AUTOSAR XML (schema 4-3-0)
package /Comp_FDC_ARPkg
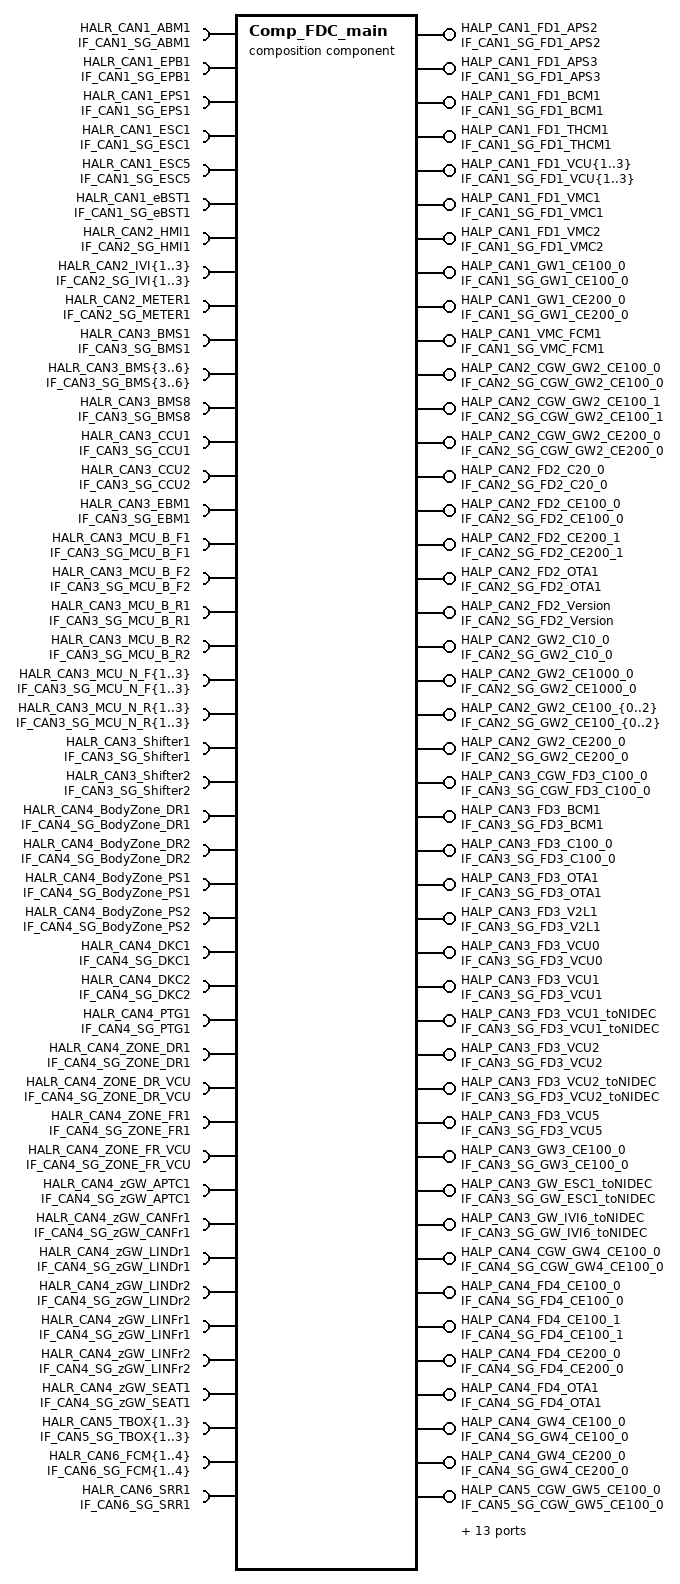
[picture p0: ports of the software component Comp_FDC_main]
  composition sw component type Comp_FDC_main
    63 x provide port:
      HALP_CAN1_FD1_APS2: nonqueued-sender-com-spec{data-element=CAN1_SG_FD1_APS2, handle-out-of-range=DEFAULT, init-value=constant-reference=Init_CAN1_SG_FD1_APS2}, provided-interface=IF_CAN1_SG_FD1_APS2
      HALP_CAN1_FD1_APS3: nonqueued-sender-com-spec{data-element=CAN1_SG_FD1_APS3, handle-out-of-range=DEFAULT, init-value=constant-reference=Init_CAN1_SG_FD1_APS3}, provided-interface=IF_CAN1_SG_FD1_APS3
      HALP_CAN1_FD1_BCM1: nonqueued-sender-com-spec{data-element=CAN1_SG_FD1_BCM1, handle-out-of-range=DEFAULT, init-value=constant-reference=Init_CAN1_SG_FD1_BCM1}, provided-interface=IF_CAN1_SG_FD1_BCM1
      HALP_CAN1_FD1_THCM1: nonqueued-sender-com-spec{data-element=CAN1_SG_FD1_THCM1, handle-out-of-range=DEFAULT, init-value=constant-reference=Init_CAN1_SG_FD1_THCM1}, provided-interface=IF_CAN1_SG_FD1_THCM1
      HALP_CAN1_FD1_VCU{1..3}: nonqueued-sender-com-spec{data-element=CAN1_SG_FD1_VCU{1..3}, handle-out-of-range=DEFAULT, init-value=constant-reference=Init_CAN1_SG_FD1_VCU{1..3}}, provided-interface=IF_CAN1_SG_FD1_VCU{1..3}
      HALP_CAN1_FD1_VMC1: nonqueued-sender-com-spec{data-element=CAN1_SG_FD1_VMC1, handle-out-of-range=DEFAULT, init-value=constant-reference=Init_CAN1_SG_FD1_VMC1}, provided-interface=IF_CAN1_SG_FD1_VMC1
      HALP_CAN1_FD1_VMC2: nonqueued-sender-com-spec{data-element=CAN1_SG_FD1_VMC2, handle-out-of-range=DEFAULT, init-value=constant-reference=Init_CAN1_SG_FD1_VMC2}, provided-interface=IF_CAN1_SG_FD1_VMC2
      HALP_CAN1_GW1_CE100_0: nonqueued-sender-com-spec{data-element=CAN1_SG_GW1_CE100_0, handle-out-of-range=DEFAULT, init-value=constant-reference=Init_CAN1_SG_GW1_CE100_0}, provided-interface=IF_CAN1_SG_GW1_CE100_0
      HALP_CAN1_GW1_CE200_0: nonqueued-sender-com-spec{data-element=CAN1_SG_GW1_CE200_0, handle-out-of-range=DEFAULT, init-value=constant-reference=Init_CAN1_SG_GW1_CE200_0}, provided-interface=IF_CAN1_SG_GW1_CE200_0
      HALP_CAN1_VMC_FCM1: nonqueued-sender-com-spec{data-element=CAN1_SG_VMC_FCM1, handle-out-of-range=DEFAULT, init-value=constant-reference=Init_CAN1_SG_VMC_FCM1}, provided-interface=IF_CAN1_SG_VMC_FCM1
      HALP_CAN2_CGW_GW2_CE100_0: nonqueued-sender-com-spec{data-element=CAN2_SG_CGW_GW2_CE100_0, handle-out-of-range=DEFAULT, init-value=constant-reference=Init_CAN2_SG_CGW_GW2_CE100_0}, provided-interface=IF_CAN2_SG_CGW_GW2_CE100_0
      HALP_CAN2_CGW_GW2_CE100_1: nonqueued-sender-com-spec{data-element=CAN2_SG_CGW_GW2_CE100_1, handle-out-of-range=DEFAULT, init-value=constant-reference=Init_CAN2_SG_CGW_GW2_CE100_1}, provided-interface=IF_CAN2_SG_CGW_GW2_CE100_1
      HALP_CAN2_CGW_GW2_CE200_0: nonqueued-sender-com-spec{data-element=CAN2_SG_CGW_GW2_CE200_0, handle-out-of-range=DEFAULT, init-value=constant-reference=Init_CAN2_SG_CGW_GW2_CE200_0}, provided-interface=IF_CAN2_SG_CGW_GW2_CE200_0
      HALP_CAN2_FD2_C20_0: nonqueued-sender-com-spec{data-element=CAN2_SG_FD2_C20_0, handle-out-of-range=DEFAULT, init-value=constant-reference=Init_CAN2_SG_FD2_C20_0}, provided-interface=IF_CAN2_SG_FD2_C20_0
      HALP_CAN2_FD2_CE100_0: nonqueued-sender-com-spec{data-element=CAN2_SG_FD2_CE100_0, handle-out-of-range=DEFAULT, init-value=constant-reference=Init_CAN2_SG_FD2_CE100_0}, provided-interface=IF_CAN2_SG_FD2_CE100_0
      HALP_CAN2_FD2_CE200_1: nonqueued-sender-com-spec{data-element=CAN2_SG_FD2_CE200_1, handle-out-of-range=DEFAULT, init-value=constant-reference=Init_CAN2_SG_FD2_CE200_1}, provided-interface=IF_CAN2_SG_FD2_CE200_1
      HALP_CAN2_FD2_OTA1: nonqueued-sender-com-spec{data-element=CAN2_SG_FD2_OTA1, handle-out-of-range=DEFAULT, init-value=constant-reference=Init_CAN2_SG_FD2_OTA1}, provided-interface=IF_CAN2_SG_FD2_OTA1
      HALP_CAN2_FD2_Version: nonqueued-sender-com-spec{data-element=CAN2_SG_FD2_Version, handle-out-of-range=DEFAULT, init-value=constant-reference=Init_CAN2_SG_FD2_Version}, provided-interface=IF_CAN2_SG_FD2_Version
      HALP_CAN2_GW2_C10_0: nonqueued-sender-com-spec{data-element=CAN2_SG_GW2_C10_0, handle-out-of-range=DEFAULT, init-value=constant-reference=Init_CAN2_SG_GW2_C10_0}, provided-interface=IF_CAN2_SG_GW2_C10_0
      HALP_CAN2_GW2_CE1000_0: nonqueued-sender-com-spec{data-element=CAN2_SG_GW2_CE1000_0, handle-out-of-range=DEFAULT, init-value=constant-reference=Init_CAN2_SG_GW2_CE1000_0}, provided-interface=IF_CAN2_SG_GW2_CE1000_0
      HALP_CAN2_GW2_CE100_{0..2}: nonqueued-sender-com-spec{data-element=CAN2_SG_GW2_CE100_{0..2}, handle-out-of-range=DEFAULT, init-value=constant-reference=Init_CAN2_SG_GW2_CE100_{0..2}}, provided-interface=IF_CAN2_SG_GW2_CE100_{0..2}
      HALP_CAN2_GW2_CE200_0: nonqueued-sender-com-spec{data-element=CAN2_SG_GW2_CE200_0, handle-out-of-range=DEFAULT, init-value=constant-reference=Init_CAN2_SG_GW2_CE200_0}, provided-interface=IF_CAN2_SG_GW2_CE200_0
      HALP_CAN3_CGW_FD3_C100_0: nonqueued-sender-com-spec{data-element=CAN3_SG_CGW_FD3_C100_0, handle-out-of-range=DEFAULT, init-value=constant-reference=Init_CAN3_SG_CGW_FD3_C100_0}, provided-interface=IF_CAN3_SG_CGW_FD3_C100_0
      HALP_CAN3_FD3_BCM1: nonqueued-sender-com-spec{data-element=CAN3_SG_FD3_BCM1, handle-out-of-range=DEFAULT, init-value=constant-reference=Init_CAN3_SG_FD3_BCM1}, provided-interface=IF_CAN3_SG_FD3_BCM1
      HALP_CAN3_FD3_C100_0: nonqueued-sender-com-spec{data-element=CAN3_SG_FD3_C100_0, handle-out-of-range=DEFAULT, init-value=constant-reference=Init_CAN3_SG_FD3_C100_0}, provided-interface=IF_CAN3_SG_FD3_C100_0
      HALP_CAN3_FD3_OTA1: nonqueued-sender-com-spec{data-element=CAN3_SG_FD3_OTA1, handle-out-of-range=DEFAULT, init-value=constant-reference=Init_CAN3_SG_FD3_OTA1}, provided-interface=IF_CAN3_SG_FD3_OTA1
      HALP_CAN3_FD3_V2L1: nonqueued-sender-com-spec{data-element=CAN3_SG_FD3_V2L1, handle-out-of-range=DEFAULT, init-value=constant-reference=Init_CAN3_SG_FD3_V2L1}, provided-interface=IF_CAN3_SG_FD3_V2L1
      HALP_CAN3_FD3_VCU0: nonqueued-sender-com-spec{data-element=CAN3_SG_FD3_VCU0, handle-out-of-range=DEFAULT, init-value=constant-reference=Init_CAN3_SG_FD3_VCU0}, provided-interface=IF_CAN3_SG_FD3_VCU0
      HALP_CAN3_FD3_VCU1: nonqueued-sender-com-spec{data-element=CAN3_SG_FD3_VCU1, handle-out-of-range=DEFAULT, init-value=constant-reference=Init_CAN3_SG_FD3_VCU1}, provided-interface=IF_CAN3_SG_FD3_VCU1
      HALP_CAN3_FD3_VCU1_toNIDEC: nonqueued-sender-com-spec{data-element=CAN3_SG_FD3_VCU1_toNIDEC, handle-out-of-range=DEFAULT, init-value=constant-reference=Init_CAN3_SG_FD3_VCU1_toNIDEC}, provided-interface=IF_CAN3_SG_FD3_VCU1_toNIDEC
      HALP_CAN3_FD3_VCU2: nonqueued-sender-com-spec{data-element=CAN3_SG_FD3_VCU2, handle-out-of-range=DEFAULT, init-value=constant-reference=Init_CAN3_SG_FD3_VCU2}, provided-interface=IF_CAN3_SG_FD3_VCU2
      HALP_CAN3_FD3_VCU2_toNIDEC: nonqueued-sender-com-spec{data-element=CAN3_SG_FD3_VCU2_toNIDEC, handle-out-of-range=DEFAULT, init-value=constant-reference=Init_CAN3_SG_FD3_VCU2_toNIDEC}, provided-interface=IF_CAN3_SG_FD3_VCU2_toNIDEC
      HALP_CAN3_FD3_VCU5: nonqueued-sender-com-spec{data-element=CAN3_SG_FD3_VCU5, handle-out-of-range=DEFAULT, init-value=constant-reference=Init_CAN3_SG_FD3_VCU5}, provided-interface=IF_CAN3_SG_FD3_VCU5
      HALP_CAN3_GW3_CE100_0: nonqueued-sender-com-spec{data-element=CAN3_SG_GW3_CE100_0, handle-out-of-range=DEFAULT, init-value=constant-reference=Init_CAN3_SG_GW3_CE100_0}, provided-interface=IF_CAN3_SG_GW3_CE100_0
      HALP_CAN3_GW_ESC1_toNIDEC: nonqueued-sender-com-spec{data-element=CAN3_SG_GW_ESC1_toNIDEC, handle-out-of-range=DEFAULT, init-value=constant-reference=Init_CAN3_SG_GW_ESC1_toNIDEC}, provided-interface=IF_CAN3_SG_GW_ESC1_toNIDEC
      HALP_CAN3_GW_IVI6_toNIDEC: nonqueued-sender-com-spec{data-element=CAN3_SG_GW_IVI6_toNIDEC, handle-out-of-range=DEFAULT, init-value=constant-reference=Init_CAN3_SG_GW_IVI6_toNIDEC}, provided-interface=IF_CAN3_SG_GW_IVI6_toNIDEC
      HALP_CAN4_CGW_GW4_CE100_0: nonqueued-sender-com-spec{data-element=CAN4_SG_CGW_GW4_CE100_0, handle-out-of-range=DEFAULT, init-value=constant-reference=Init_CAN4_SG_CGW_GW4_CE100_0}, provided-interface=IF_CAN4_SG_CGW_GW4_CE100_0
      HALP_CAN4_FD4_CE100_0: nonqueued-sender-com-spec{data-element=CAN4_SG_FD4_CE100_0, handle-out-of-range=DEFAULT, init-value=constant-reference=Init_CAN4_SG_FD4_CE100_0}, provided-interface=IF_CAN4_SG_FD4_CE100_0
      HALP_CAN4_FD4_CE100_1: nonqueued-sender-com-spec{data-element=CAN4_SG_FD4_CE100_1, handle-out-of-range=DEFAULT, init-value=constant-reference=Init_CAN4_SG_FD4_CE100_1}, provided-interface=IF_CAN4_SG_FD4_CE100_1
      HALP_CAN4_FD4_CE200_0: nonqueued-sender-com-spec{data-element=CAN4_SG_FD4_CE200_0, handle-out-of-range=DEFAULT, init-value=constant-reference=Init_CAN4_SG_FD4_CE200_0}, provided-interface=IF_CAN4_SG_FD4_CE200_0
      HALP_CAN4_FD4_OTA1: nonqueued-sender-com-spec{data-element=CAN4_SG_FD4_OTA1, handle-out-of-range=DEFAULT, init-value=constant-reference=Init_CAN4_SG_FD4_OTA1}, provided-interface=IF_CAN4_SG_FD4_OTA1
      HALP_CAN4_GW4_CE100_0: nonqueued-sender-com-spec{data-element=CAN4_SG_GW4_CE100_0, handle-out-of-range=DEFAULT, init-value=constant-reference=Init_CAN4_SG_GW4_CE100_0}, provided-interface=IF_CAN4_SG_GW4_CE100_0
      HALP_CAN4_GW4_CE200_0: nonqueued-sender-com-spec{data-element=CAN4_SG_GW4_CE200_0, handle-out-of-range=DEFAULT, init-value=constant-reference=Init_CAN4_SG_GW4_CE200_0}, provided-interface=IF_CAN4_SG_GW4_CE200_0
      HALP_CAN5_CGW_GW5_CE100_0: nonqueued-sender-com-spec{data-element=CAN5_SG_CGW_GW5_CE100_0, handle-out-of-range=DEFAULT, init-value=constant-reference=Init_CAN5_SG_CGW_GW5_CE100_0}, provided-interface=IF_CAN5_SG_CGW_GW5_CE100_0
      HALP_CAN5_FD5_CE100_0: nonqueued-sender-com-spec{data-element=CAN5_SG_FD5_CE100_0, handle-out-of-range=DEFAULT, init-value=constant-reference=Init_CAN5_SG_FD5_CE100_0}, provided-interface=IF_CAN5_SG_FD5_CE100_0
      HALP_CAN5_FD5_CONN1: nonqueued-sender-com-spec{data-element=CAN5_SG_FD5_CONN1, handle-out-of-range=DEFAULT, init-value=constant-reference=Init_CAN5_SG_FD5_CONN1}, provided-interface=IF_CAN5_SG_FD5_CONN1
      HALP_CAN5_FD5_Debug{1..3}: nonqueued-sender-com-spec{data-element=CAN5_SG_FD5_Debug{1..3}, handle-out-of-range=DEFAULT, init-value=constant-reference=Init_CAN5_SG_FD5_Debug{1..3}}, provided-interface=IF_CAN5_SG_FD5_Debug{1..3}
      HALP_CAN5_FD5_OTA1: nonqueued-sender-com-spec{data-element=CAN5_SG_FD5_OTA1, handle-out-of-range=DEFAULT, init-value=constant-reference=Init_CAN5_SG_FD5_OTA1}, provided-interface=IF_CAN5_SG_FD5_OTA1
      HALP_CAN5_GW5_CE100_0: nonqueued-sender-com-spec{data-element=CAN5_SG_GW5_CE100_0, handle-out-of-range=DEFAULT, init-value=constant-reference=Init_CAN5_SG_GW5_CE100_0}, provided-interface=IF_CAN5_SG_GW5_CE100_0
      HALP_CAN6_CGW_GW6_CE100_0: nonqueued-sender-com-spec{data-element=CAN6_SG_CGW_GW6_CE100_0, handle-out-of-range=DEFAULT, init-value=constant-reference=Init_CAN6_SG_CGW_GW6_CE100_0}, provided-interface=IF_CAN6_SG_CGW_GW6_CE100_0
      HALP_CAN6_FD6_APS3: nonqueued-sender-com-spec{data-element=CAN6_SG_FD6_APS3, handle-out-of-range=DEFAULT, init-value=constant-reference=Init_CAN6_SG_FD6_APS3}, provided-interface=IF_CAN6_SG_FD6_APS3
      HALP_CAN6_FD6_BCM1: nonqueued-sender-com-spec{data-element=CAN6_SG_FD6_BCM1, handle-out-of-range=DEFAULT, init-value=constant-reference=Init_CAN6_SG_FD6_BCM1}, provided-interface=IF_CAN6_SG_FD6_BCM1
      HALP_CAN6_FD6_VCU1: nonqueued-sender-com-spec{data-element=CAN6_SG_FD6_VCU1, handle-out-of-range=DEFAULT, init-value=constant-reference=Init_CAN6_SG_FD6_VCU1}, provided-interface=IF_CAN6_SG_FD6_VCU1
      HALP_CAN6_FD6_VCU2: nonqueued-sender-com-spec{data-element=CAN6_SG_FD6_VCU2, handle-out-of-range=DEFAULT, init-value=constant-reference=Init_CAN6_SG_FD6_VCU2}, provided-interface=IF_CAN6_SG_FD6_VCU2
      HALP_CAN6_FD6_VMC1: nonqueued-sender-com-spec{data-element=CAN6_SG_FD6_VMC1, handle-out-of-range=DEFAULT, init-value=constant-reference=Init_CAN6_SG_FD6_VMC1}, provided-interface=IF_CAN6_SG_FD6_VMC1
      HALP_CAN6_GW6_CE100_0: nonqueued-sender-com-spec{data-element=CAN6_SG_GW6_CE100_0, handle-out-of-range=DEFAULT, init-value=constant-reference=Init_CAN6_SG_GW6_CE100_0}, provided-interface=IF_CAN6_SG_GW6_CE100_0
      HALP_CAN7_GW7_C100_0: nonqueued-sender-com-spec{data-element=CAN7_SG_GW7_C100_0, handle-out-of-range=DEFAULT, init-value=constant-reference=Init_CAN7_SG_GW7_C100_0}, provided-interface=IF_CAN7_SG_GW7_C100_0
    58 x require port:
      HALR_CAN1_ABM1: nonqueued-receiver-com-spec{data-element=CAN1_SG_ABM1, handle-out-of-range=DEFAULT, enable-update=true, init-value=constant-reference=Init_CAN1_SG_ABM1}, required-interface=IF_CAN1_SG_ABM1
      HALR_CAN1_EPB1: nonqueued-receiver-com-spec{data-element=CAN1_SG_EPB1, handle-out-of-range=DEFAULT, enable-update=true, init-value=constant-reference=Init_CAN1_SG_EPB1}, required-interface=IF_CAN1_SG_EPB1
      HALR_CAN1_EPS1: nonqueued-receiver-com-spec{data-element=CAN1_SG_EPS1, handle-out-of-range=DEFAULT, enable-update=true, init-value=constant-reference=Init_CAN1_SG_EPS1}, required-interface=IF_CAN1_SG_EPS1
      HALR_CAN1_ESC1: nonqueued-receiver-com-spec{data-element=CAN1_SG_ESC1, handle-out-of-range=DEFAULT, enable-update=true, init-value=constant-reference=Init_CAN1_SG_ESC1}, required-interface=IF_CAN1_SG_ESC1
      HALR_CAN1_ESC5: nonqueued-receiver-com-spec{data-element=CAN1_SG_ESC5, handle-out-of-range=DEFAULT, enable-update=true, init-value=constant-reference=Init_CAN1_SG_ESC5}, required-interface=IF_CAN1_SG_ESC5
      HALR_CAN1_eBST1: nonqueued-receiver-com-spec{data-element=CAN1_SG_eBST1, handle-out-of-range=DEFAULT, enable-update=true, init-value=constant-reference=Init_CAN1_SG_eBST1}, required-interface=IF_CAN1_SG_eBST1
      HALR_CAN2_HMI1: nonqueued-receiver-com-spec{data-element=CAN2_SG_HMI1, handle-out-of-range=DEFAULT, enable-update=true, init-value=constant-reference=Init_CAN2_SG_HMI1}, required-interface=IF_CAN2_SG_HMI1
      HALR_CAN2_IVI{1..3}: nonqueued-receiver-com-spec{data-element=CAN2_SG_IVI{1..3}, handle-out-of-range=DEFAULT, enable-update=true, init-value=constant-reference=Init_CAN2_SG_IVI{1..3}}, required-interface=IF_CAN2_SG_IVI{1..3}
      HALR_CAN2_METER1: nonqueued-receiver-com-spec{data-element=CAN2_SG_METER1, handle-out-of-range=DEFAULT, enable-update=true, init-value=constant-reference=Init_CAN2_SG_METER1}, required-interface=IF_CAN2_SG_METER1
      HALR_CAN3_BMS1: nonqueued-receiver-com-spec{data-element=CAN3_SG_BMS1, handle-out-of-range=DEFAULT, enable-update=true, init-value=constant-reference=Init_CAN3_SG_BMS1}, required-interface=IF_CAN3_SG_BMS1
      HALR_CAN3_BMS{3..6}: nonqueued-receiver-com-spec{data-element=CAN3_SG_BMS{3..6}, handle-out-of-range=DEFAULT, enable-update=true, init-value=constant-reference=Init_CAN3_SG_BMS{3..6}}, required-interface=IF_CAN3_SG_BMS{3..6}
      HALR_CAN3_BMS8: nonqueued-receiver-com-spec{data-element=CAN3_SG_BMS8, handle-out-of-range=DEFAULT, enable-update=true, init-value=constant-reference=Init_CAN3_SG_BMS8}, required-interface=IF_CAN3_SG_BMS8
      HALR_CAN3_CCU1: nonqueued-receiver-com-spec{data-element=CAN3_SG_CCU1, handle-out-of-range=DEFAULT, enable-update=true, init-value=constant-reference=Init_CAN3_SG_CCU1}, required-interface=IF_CAN3_SG_CCU1
      HALR_CAN3_CCU2: nonqueued-receiver-com-spec{data-element=CAN3_SG_CCU2, handle-out-of-range=DEFAULT, enable-update=true, init-value=constant-reference=Init_CAN3_SG_CCU2}, required-interface=IF_CAN3_SG_CCU2
      HALR_CAN3_EBM1: nonqueued-receiver-com-spec{data-element=CAN3_SG_EBM1, handle-out-of-range=DEFAULT, enable-update=true, init-value=constant-reference=Init_CAN3_SG_EBM1}, required-interface=IF_CAN3_SG_EBM1
      HALR_CAN3_MCU_B_F1: nonqueued-receiver-com-spec{data-element=CAN3_SG_MCU_B_F1, handle-out-of-range=DEFAULT, enable-update=true, init-value=constant-reference=Init_CAN3_SG_MCU_B_F1}, required-interface=IF_CAN3_SG_MCU_B_F1
      HALR_CAN3_MCU_B_F2: nonqueued-receiver-com-spec{data-element=CAN3_SG_MCU_B_F2, handle-out-of-range=DEFAULT, enable-update=true, init-value=constant-reference=Init_CAN3_SG_MCU_B_F2}, required-interface=IF_CAN3_SG_MCU_B_F2
      HALR_CAN3_MCU_B_R1: nonqueued-receiver-com-spec{data-element=CAN3_SG_MCU_B_R1, handle-out-of-range=DEFAULT, enable-update=true, init-value=constant-reference=Init_CAN3_SG_MCU_B_R1}, required-interface=IF_CAN3_SG_MCU_B_R1
      HALR_CAN3_MCU_B_R2: nonqueued-receiver-com-spec{data-element=CAN3_SG_MCU_B_R2, handle-out-of-range=DEFAULT, enable-update=true, init-value=constant-reference=Init_CAN3_SG_MCU_B_R2}, required-interface=IF_CAN3_SG_MCU_B_R2
      HALR_CAN3_MCU_N_F{1..3}: nonqueued-receiver-com-spec{data-element=CAN3_SG_MCU_N_F{1..3}, handle-out-of-range=DEFAULT, enable-update=true, init-value=constant-reference=Init_CAN3_SG_MCU_N_F{1..3}}, required-interface=IF_CAN3_SG_MCU_N_F{1..3}
      HALR_CAN3_MCU_N_R{1..3}: nonqueued-receiver-com-spec{data-element=CAN3_SG_MCU_N_R{1..3}, handle-out-of-range=DEFAULT, enable-update=true, init-value=constant-reference=Init_CAN3_SG_MCU_N_R{1..3}}, required-interface=IF_CAN3_SG_MCU_N_R{1..3}
      HALR_CAN3_Shifter1: nonqueued-receiver-com-spec{data-element=CAN3_SG_Shifter1, handle-out-of-range=DEFAULT, enable-update=true, init-value=constant-reference=Init_CAN3_SG_Shifter1}, required-interface=IF_CAN3_SG_Shifter1
      HALR_CAN3_Shifter2: nonqueued-receiver-com-spec{data-element=CAN3_SG_Shifter2, handle-out-of-range=DEFAULT, enable-update=true, init-value=constant-reference=Init_CAN3_SG_Shifter2}, required-interface=IF_CAN3_SG_Shifter2
      HALR_CAN4_BodyZone_DR1: nonqueued-receiver-com-spec{data-element=CAN4_SG_BodyZone_DR1, handle-out-of-range=DEFAULT, enable-update=true, init-value=constant-reference=Init_CAN4_SG_BodyZone_DR1}, required-interface=IF_CAN4_SG_BodyZone_DR1
      HALR_CAN4_BodyZone_DR2: nonqueued-receiver-com-spec{data-element=CAN4_SG_BodyZone_DR2, handle-out-of-range=DEFAULT, enable-update=true, init-value=constant-reference=Init_CAN4_SG_BodyZone_DR2}, required-interface=IF_CAN4_SG_BodyZone_DR2
      HALR_CAN4_BodyZone_PS1: nonqueued-receiver-com-spec{data-element=CAN4_SG_BodyZone_PS1, handle-out-of-range=DEFAULT, enable-update=true, init-value=constant-reference=Init_CAN4_SG_BodyZone_PS1}, required-interface=IF_CAN4_SG_BodyZone_PS1
      HALR_CAN4_BodyZone_PS2: nonqueued-receiver-com-spec{data-element=CAN4_SG_BodyZone_PS2, handle-out-of-range=DEFAULT, enable-update=true, init-value=constant-reference=Init_CAN4_SG_BodyZone_PS2}, required-interface=IF_CAN4_SG_BodyZone_PS2
      HALR_CAN4_DKC1: nonqueued-receiver-com-spec{data-element=CAN4_SG_DKC1, handle-out-of-range=DEFAULT, enable-update=true, init-value=constant-reference=Init_CAN4_SG_DKC1}, required-interface=IF_CAN4_SG_DKC1
      HALR_CAN4_DKC2: nonqueued-receiver-com-spec{data-element=CAN4_SG_DKC2, handle-out-of-range=DEFAULT, enable-update=true, init-value=constant-reference=Init_CAN4_SG_DKC2}, required-interface=IF_CAN4_SG_DKC2
      HALR_CAN4_PTG1: nonqueued-receiver-com-spec{data-element=CAN4_SG_PTG1, handle-out-of-range=DEFAULT, enable-update=true, init-value=constant-reference=Init_CAN4_SG_PTG1}, required-interface=IF_CAN4_SG_PTG1
      HALR_CAN4_ZONE_DR1: nonqueued-receiver-com-spec{data-element=CAN4_SG_ZONE_DR1, handle-out-of-range=DEFAULT, enable-update=true, init-value=constant-reference=Init_CAN4_SG_ZONE_DR1}, required-interface=IF_CAN4_SG_ZONE_DR1
      HALR_CAN4_ZONE_DR_VCU: nonqueued-receiver-com-spec{data-element=CAN4_SG_ZONE_DR_VCU, handle-out-of-range=DEFAULT, enable-update=true, init-value=constant-reference=Init_CAN4_SG_ZONE_DR_VCU}, required-interface=IF_CAN4_SG_ZONE_DR_VCU
      HALR_CAN4_ZONE_FR1: nonqueued-receiver-com-spec{data-element=CAN4_SG_ZONE_FR1, handle-out-of-range=DEFAULT, enable-update=true, init-value=constant-reference=Init_CAN4_SG_ZONE_FR1}, required-interface=IF_CAN4_SG_ZONE_FR1
      HALR_CAN4_ZONE_FR_VCU: nonqueued-receiver-com-spec{data-element=CAN4_SG_ZONE_FR_VCU, handle-out-of-range=DEFAULT, enable-update=true, init-value=constant-reference=Init_CAN4_SG_ZONE_FR_VCU}, required-interface=IF_CAN4_SG_ZONE_FR_VCU
      HALR_CAN4_zGW_APTC1: nonqueued-receiver-com-spec{data-element=CAN4_SG_zGW_APTC1, handle-out-of-range=DEFAULT, enable-update=true, init-value=constant-reference=Init_CAN4_SG_zGW_APTC1}, required-interface=IF_CAN4_SG_zGW_APTC1
      HALR_CAN4_zGW_CANFr1: nonqueued-receiver-com-spec{data-element=CAN4_SG_zGW_CANFr1, handle-out-of-range=DEFAULT, enable-update=true, init-value=constant-reference=Init_CAN4_SG_zGW_CANFr1}, required-interface=IF_CAN4_SG_zGW_CANFr1
      HALR_CAN4_zGW_LINDr1: nonqueued-receiver-com-spec{data-element=CAN4_SG_zGW_LINDr1, handle-out-of-range=DEFAULT, enable-update=true, init-value=constant-reference=Init_CAN4_SG_zGW_LINDr1}, required-interface=IF_CAN4_SG_zGW_LINDr1
      HALR_CAN4_zGW_LINDr2: nonqueued-receiver-com-spec{data-element=CAN4_SG_zGW_LINDr2, handle-out-of-range=DEFAULT, enable-update=true, init-value=constant-reference=Init_CAN4_SG_zGW_LINDr2}, required-interface=IF_CAN4_SG_zGW_LINDr2
      HALR_CAN4_zGW_LINFr1: nonqueued-receiver-com-spec{data-element=CAN4_SG_zGW_LINFr1, handle-out-of-range=DEFAULT, enable-update=true, init-value=constant-reference=Init_CAN4_SG_zGW_LINFr1}, required-interface=IF_CAN4_SG_zGW_LINFr1
      HALR_CAN4_zGW_LINFr2: nonqueued-receiver-com-spec{data-element=CAN4_SG_zGW_LINFr2, handle-out-of-range=DEFAULT, enable-update=true, init-value=constant-reference=Init_CAN4_SG_zGW_LINFr2}, required-interface=IF_CAN4_SG_zGW_LINFr2
      HALR_CAN4_zGW_SEAT1: nonqueued-receiver-com-spec{data-element=CAN4_SG_zGW_SEAT1, handle-out-of-range=DEFAULT, enable-update=true, init-value=constant-reference=Init_CAN4_SG_zGW_SEAT1}, required-interface=IF_CAN4_SG_zGW_SEAT1
      HALR_CAN5_TBOX{1..3}: nonqueued-receiver-com-spec{data-element=CAN5_SG_TBOX{1..3}, handle-out-of-range=DEFAULT, enable-update=true, init-value=constant-reference=Init_CAN5_SG_TBOX{1..3}}, required-interface=IF_CAN5_SG_TBOX{1..3}
      HALR_CAN6_FCM{1..4}: nonqueued-receiver-com-spec{data-element=CAN6_SG_FCM{1..4}, handle-out-of-range=DEFAULT, enable-update=true, init-value=constant-reference=Init_CAN6_SG_FCM{1..4}}, required-interface=IF_CAN6_SG_FCM{1..4}
      HALR_CAN6_SRR1: nonqueued-receiver-com-spec{data-element=CAN6_SG_SRR1, handle-out-of-range=DEFAULT, enable-update=true, init-value=constant-reference=Init_CAN6_SG_SRR1}, required-interface=IF_CAN6_SG_SRR1
    23 x component:
      BswMTest: type=BswMTest_type
      SWC_CDD: type=SWC_CDD_type
      SWC_CGW: type=SWC_CGW_type
      SWC_DID: type=SWC_DID_type
      SWC_DKC: type=SWC_DKC_type
      SWC_FDC: type=SWC_FDC_type
      SWC_HALIN: type=SWC_HALIN_type
      SWC_HALIN_CDD: type=SWC_HALIN_CDD_type
      SWC_IMU: type=SWC_IMU_type
      SWC_INP: type=SWC_INP_type
      SWC_IOEXP: type=SWC_IOEXP_type
      SWC_OUTP: type=SWC_OUTP_type
      SWC_HALOUT: type=SWC_HALOUT_type
      SWC_LOG: type=SWC_LOG_type
      SWC_NVM: type=SWC_NVM_type
      SWC_SCP: type=SWC_SCP_type
      SWC_UART: type=SWC_UART_type
      SWC_UDS: type=SWC_UDS_type
      SWC_VES: type=SWC_VES_type
      SWC_V2L: type=SWC_V2L_type
      SWC_CARB: type=SWC_CARB_type
      SWC_DDM: type=SWC_DDM_type
      SWC_TPMS_APS: type=SWC_TPMS_APS_type
    delegate SWC_HALIN.R_CAN1_ABM1 <-> outer port HALR_CAN1_ABM1
    delegate SWC_HALIN.R_CAN1_EPB1 <-> outer port HALR_CAN1_EPB1
    delegate SWC_HALIN.R_CAN1_EPS1 <-> outer port HALR_CAN1_EPS1
    delegate SWC_HALIN.R_CAN1_ESC1 <-> outer port HALR_CAN1_ESC1
    delegate SWC_HALIN.R_CAN1_ESC5 <-> outer port HALR_CAN1_ESC5
    delegate SWC_HALIN.R_CAN1_eBST1 <-> outer port HALR_CAN1_eBST1
    delegate SWC_HALIN.R_CAN2_HMI1 <-> outer port HALR_CAN2_HMI1
    delegate SWC_HALIN.R_CAN2_IVI{1..3} <-> outer port HALR_CAN2_IVI{1..3}
    delegate SWC_HALIN.R_CAN2_METER1 <-> outer port HALR_CAN2_METER1
    delegate SWC_HALIN.R_CAN3_BMS1 <-> outer port HALR_CAN3_BMS1
    delegate SWC_HALIN.R_CAN3_BMS{3..6} <-> outer port HALR_CAN3_BMS{3..6}
    delegate SWC_HALIN.R_CAN3_BMS8 <-> outer port HALR_CAN3_BMS8
    delegate SWC_HALIN.R_CAN3_CCU1 <-> outer port HALR_CAN3_CCU1
    delegate SWC_HALIN.R_CAN3_CCU2 <-> outer port HALR_CAN3_CCU2
    delegate SWC_HALIN.R_CAN3_EBM1 <-> outer port HALR_CAN3_EBM1
    delegate SWC_HALIN.R_CAN3_MCU_B_F1 <-> outer port HALR_CAN3_MCU_B_F1
    delegate SWC_HALIN.R_CAN3_MCU_B_F2 <-> outer port HALR_CAN3_MCU_B_F2
    delegate SWC_HALIN.R_CAN3_MCU_B_R1 <-> outer port HALR_CAN3_MCU_B_R1
    delegate SWC_HALIN.R_CAN3_MCU_B_R2 <-> outer port HALR_CAN3_MCU_B_R2
    delegate SWC_HALIN.R_CAN3_MCU_N_F{1..3} <-> outer port HALR_CAN3_MCU_N_F{1..3}
    delegate SWC_HALIN.R_CAN3_MCU_N_R{1..3} <-> outer port HALR_CAN3_MCU_N_R{1..3}
    delegate SWC_HALIN.R_CAN3_Shifter1 <-> outer port HALR_CAN3_Shifter1
    delegate SWC_HALIN.R_CAN3_Shifter2 <-> outer port HALR_CAN3_Shifter2
    delegate SWC_HALIN.R_CAN4_BodyZone_DR1 <-> outer port HALR_CAN4_BodyZone_DR1
    delegate SWC_HALIN.R_CAN4_BodyZone_DR2 <-> outer port HALR_CAN4_BodyZone_DR2
    delegate SWC_HALIN.R_CAN4_BodyZone_PS1 <-> outer port HALR_CAN4_BodyZone_PS1
    delegate SWC_HALIN.R_CAN4_BodyZone_PS2 <-> outer port HALR_CAN4_BodyZone_PS2
    delegate SWC_HALIN.R_CAN4_DKC1 <-> outer port HALR_CAN4_DKC1
    delegate SWC_HALIN.R_CAN4_DKC2 <-> outer port HALR_CAN4_DKC2
    delegate SWC_HALIN.R_CAN4_PTG1 <-> outer port HALR_CAN4_PTG1
    delegate SWC_HALIN.R_CAN4_ZONE_DR1 <-> outer port HALR_CAN4_ZONE_DR1
    delegate SWC_HALIN.R_CAN4_ZONE_DR_VCU <-> outer port HALR_CAN4_ZONE_DR_VCU
    delegate SWC_HALIN.R_CAN4_ZONE_FR1 <-> outer port HALR_CAN4_ZONE_FR1
    delegate SWC_HALIN.R_CAN4_ZONE_FR_VCU <-> outer port HALR_CAN4_ZONE_FR_VCU
    delegate SWC_HALIN.R_CAN4_zGW_APTC1 <-> outer port HALR_CAN4_zGW_APTC1
    delegate SWC_HALIN.R_CAN4_zGW_CANFr1 <-> outer port HALR_CAN4_zGW_CANFr1
    delegate SWC_HALIN.R_CAN4_zGW_LINDr1 <-> outer port HALR_CAN4_zGW_LINDr1
    delegate SWC_HALIN.R_CAN4_zGW_LINDr2 <-> outer port HALR_CAN4_zGW_LINDr2
    delegate SWC_HALIN.R_CAN4_zGW_LINFr1 <-> outer port HALR_CAN4_zGW_LINFr1
    delegate SWC_HALIN.R_CAN4_zGW_LINFr2 <-> outer port HALR_CAN4_zGW_LINFr2
    delegate SWC_HALIN.R_CAN4_zGW_SEAT1 <-> outer port HALR_CAN4_zGW_SEAT1
    delegate SWC_HALIN.R_CAN5_TBOX2 <-> outer port HALR_CAN5_TBOX2
    delegate SWC_HALIN.R_CAN5_TBOX3 <-> outer port HALR_CAN5_TBOX3
    delegate SWC_HALIN.R_CAN6_FCM{1..4} <-> outer port HALR_CAN6_FCM{1..4}
    delegate SWC_HALIN.R_CAN6_SRR1 <-> outer port HALR_CAN6_SRR1
    delegate SWC_CGW.R_CAN1_ABM1 <-> outer port HALR_CAN1_ABM1
    delegate SWC_CGW.R_CAN1_EPS1 <-> outer port HALR_CAN1_EPS1
    delegate SWC_CGW.R_CAN1_ESC1 <-> outer port HALR_CAN1_ESC1
    delegate SWC_CGW.R_CAN1_ESC5 <-> outer port HALR_CAN1_ESC5
    delegate SWC_CGW.R_CAN1_eBST1 <-> outer port HALR_CAN1_eBST1
    delegate SWC_CGW.R_CAN2_HMI1 <-> outer port HALR_CAN2_HMI1
    delegate SWC_CGW.R_CAN2_IVI{1..3} <-> outer port HALR_CAN2_IVI{1..3}
    delegate SWC_CGW.R_CAN2_METER1 <-> outer port HALR_CAN2_METER1
    delegate SWC_CGW.R_CAN3_BMS1 <-> outer port HALR_CAN3_BMS1
    delegate SWC_CGW.R_CAN3_BMS{3..6} <-> outer port HALR_CAN3_BMS{3..6}
    delegate SWC_CGW.R_CAN3_BMS8 <-> outer port HALR_CAN3_BMS8
    delegate SWC_CGW.R_CAN3_CCU1 <-> outer port HALR_CAN3_CCU1
    delegate SWC_CGW.R_CAN3_CCU2 <-> outer port HALR_CAN3_CCU2
    delegate SWC_CGW.R_CAN3_EBM1 <-> outer port HALR_CAN3_EBM1
    delegate SWC_CGW.R_CAN3_MCU_B_F1 <-> outer port HALR_CAN3_MCU_B_F1
    delegate SWC_CGW.R_CAN3_MCU_B_F2 <-> outer port HALR_CAN3_MCU_B_F2
    delegate SWC_CGW.R_CAN3_MCU_B_R1 <-> outer port HALR_CAN3_MCU_B_R1
    delegate SWC_CGW.R_CAN3_MCU_B_R2 <-> outer port HALR_CAN3_MCU_B_R2
    delegate SWC_CGW.R_CAN3_MCU_N_F{1..3} <-> outer port HALR_CAN3_MCU_N_F{1..3}
    delegate SWC_CGW.R_CAN3_MCU_N_R{1..3} <-> outer port HALR_CAN3_MCU_N_R{1..3}
    delegate SWC_CGW.R_CAN3_Shifter1 <-> outer port HALR_CAN3_Shifter1
    delegate SWC_CGW.R_CAN4_BodyZone_DR1 <-> outer port HALR_CAN4_BodyZone_DR1
    delegate SWC_CGW.R_CAN4_BodyZone_DR2 <-> outer port HALR_CAN4_BodyZone_DR2
    delegate SWC_CGW.R_CAN4_BodyZone_PS1 <-> outer port HALR_CAN4_BodyZone_PS1
    delegate SWC_CGW.R_CAN4_BodyZone_PS2 <-> outer port HALR_CAN4_BodyZone_PS2
    delegate SWC_CGW.R_CAN4_DKC1 <-> outer port HALR_CAN4_DKC1
    delegate SWC_CGW.R_CAN4_PTG1 <-> outer port HALR_CAN4_PTG1
    delegate SWC_CGW.R_CAN4_ZONE_DR1 <-> outer port HALR_CAN4_ZONE_DR1
    delegate SWC_CGW.R_CAN4_ZONE_DR_VCU <-> outer port HALR_CAN4_ZONE_DR_VCU
    delegate SWC_CGW.R_CAN4_ZONE_FR1 <-> outer port HALR_CAN4_ZONE_FR1
    delegate SWC_CGW.R_CAN4_ZONE_FR_VCU <-> outer port HALR_CAN4_ZONE_FR_VCU
    delegate SWC_CGW.R_CAN4_zGW_APTC1 <-> outer port HALR_CAN4_zGW_APTC1
    delegate SWC_CGW.R_CAN4_zGW_CANFr1 <-> outer port HALR_CAN4_zGW_CANFr1
    delegate SWC_CGW.R_CAN4_zGW_LINDr1 <-> outer port HALR_CAN4_zGW_LINDr1
    delegate SWC_CGW.R_CAN4_zGW_SEAT1 <-> outer port HALR_CAN4_zGW_SEAT1
    delegate SWC_CGW.R_CAN5_TBOX1 <-> outer port HALR_CAN5_TBOX1
    delegate SWC_CGW.R_CAN5_TBOX3 <-> outer port HALR_CAN5_TBOX3
    delegate SWC_CGW.R_CAN6_FCM1 <-> outer port HALR_CAN6_FCM1
    delegate SWC_HALOUT.P_CAN1_FD1_APS2 <-> outer port HALP_CAN1_FD1_APS2
    delegate SWC_HALOUT.P_CAN1_FD1_APS3 <-> outer port HALP_CAN1_FD1_APS3
    delegate SWC_HALOUT.P_CAN1_FD1_BCM1 <-> outer port HALP_CAN1_FD1_BCM1
    delegate SWC_HALOUT.P_CAN1_FD1_THCM1 <-> outer port HALP_CAN1_FD1_THCM1
    delegate SWC_HALOUT.P_CAN1_FD1_VCU{1..3} <-> outer port HALP_CAN1_FD1_VCU{1..3}
    delegate SWC_HALOUT.P_CAN1_FD1_VMC1 <-> outer port HALP_CAN1_FD1_VMC1
    delegate SWC_HALOUT.P_CAN1_FD1_VMC2 <-> outer port HALP_CAN1_FD1_VMC2
    delegate SWC_HALOUT.P_CAN1_VMC_FCM1 <-> outer port HALP_CAN1_VMC_FCM1
    delegate SWC_HALOUT.P_CAN2_FD2_C20_0 <-> outer port HALP_CAN2_FD2_C20_0
    delegate SWC_HALOUT.P_CAN2_FD2_CE100_0 <-> outer port HALP_CAN2_FD2_CE100_0
    delegate SWC_HALOUT.P_CAN2_FD2_CE200_1 <-> outer port HALP_CAN2_FD2_CE200_1
    delegate SWC_VES.P_CAN2_FD2_OTA1 <-> outer port HALP_CAN2_FD2_OTA1
    delegate SWC_HALOUT.P_CAN2_FD2_Version <-> outer port HALP_CAN2_FD2_Version
    delegate SWC_HALOUT.P_CAN2_GW2_CE100_0 <-> outer port HALP_CAN2_GW2_CE100_0
    delegate SWC_HALOUT.P_CAN2_GW2_CE100_1 <-> outer port HALP_CAN2_GW2_CE100_1
    delegate SWC_HALOUT.P_CAN2_GW2_CE200_0 <-> outer port HALP_CAN2_GW2_CE200_0
    delegate SWC_HALOUT.P_CAN3_FD3_BCM1 <-> outer port HALP_CAN3_FD3_BCM1
    delegate SWC_HALOUT.P_CAN3_FD3_C100_0 <-> outer port HALP_CAN3_FD3_C100_0
    delegate SWC_VES.P_CAN3_FD3_OTA1 <-> outer port HALP_CAN3_FD3_OTA1
    delegate SWC_HALOUT.P_CAN3_FD3_V2L1 <-> outer port HALP_CAN3_FD3_V2L1
    delegate SWC_HALOUT.P_CAN3_FD3_VCU0 <-> outer port HALP_CAN3_FD3_VCU0
    delegate SWC_HALOUT.P_CAN3_FD3_VCU1 <-> outer port HALP_CAN3_FD3_VCU1
    delegate SWC_HALOUT.P_CAN3_FD3_VCU1_toNIDEC <-> outer port HALP_CAN3_FD3_VCU1_toNIDEC
    delegate SWC_HALOUT.P_CAN3_FD3_VCU2 <-> outer port HALP_CAN3_FD3_VCU2
    delegate SWC_HALOUT.P_CAN3_FD3_VCU2_toNIDEC <-> outer port HALP_CAN3_FD3_VCU2_toNIDEC
    delegate SWC_HALOUT.P_CAN3_FD3_VCU5 <-> outer port HALP_CAN3_FD3_VCU5
    delegate SWC_HALOUT.P_CAN3_GW_ESC1_toNIDEC <-> outer port HALP_CAN3_GW_ESC1_toNIDEC
    delegate SWC_HALOUT.P_CAN3_GW_IVI6_toNIDEC <-> outer port HALP_CAN3_GW_IVI6_toNIDEC
    delegate SWC_HALOUT.P_CAN4_FD4_CE100_0 <-> outer port HALP_CAN4_FD4_CE100_0
    delegate SWC_HALOUT.P_CAN4_FD4_CE100_1 <-> outer port HALP_CAN4_FD4_CE100_1
    delegate SWC_HALOUT.P_CAN4_FD4_CE200_0 <-> outer port HALP_CAN4_FD4_CE200_0
    delegate SWC_VES.P_CAN4_FD4_OTA1 <-> outer port HALP_CAN4_FD4_OTA1
    delegate SWC_HALOUT.P_CAN4_GW4_CE100_0 <-> outer port HALP_CAN4_GW4_CE100_0
    delegate SWC_HALOUT.P_CAN5_FD5_CE100_0 <-> outer port HALP_CAN5_FD5_CE100_0
    delegate SWC_VES.P_CAN5_FD5_CONN1 <-> outer port HALP_CAN5_FD5_CONN1
    delegate SWC_HALOUT.P_CAN5_FD5_Debug{1..3} <-> outer port HALP_CAN5_FD5_Debug{1..3}
    delegate SWC_VES.P_CAN5_FD5_OTA1 <-> outer port HALP_CAN5_FD5_OTA1
    delegate SWC_HALOUT.P_CAN5_GW5_CE100_0 <-> outer port HALP_CAN5_GW5_CE100_0
    delegate SWC_HALOUT.P_CAN6_FD6_APS3 <-> outer port HALP_CAN6_FD6_APS3
    delegate SWC_HALOUT.P_CAN6_FD6_BCM1 <-> outer port HALP_CAN6_FD6_BCM1
    delegate SWC_HALOUT.P_CAN6_FD6_VCU1 <-> outer port HALP_CAN6_FD6_VCU1
    delegate SWC_HALOUT.P_CAN6_FD6_VCU2 <-> outer port HALP_CAN6_FD6_VCU2
    delegate SWC_HALOUT.P_CAN6_FD6_VMC1 <-> outer port HALP_CAN6_FD6_VMC1
    delegate SWC_HALOUT.P_CAN6_GW6_CE100_0 <-> outer port HALP_CAN6_GW6_CE100_0
    delegate SWC_CGW.P_CAN1_GW1_CE100_0 <-> outer port HALP_CAN1_GW1_CE100_0
    delegate SWC_CGW.P_CAN1_GW1_CE200_0 <-> outer port HALP_CAN1_GW1_CE200_0
    delegate SWC_CGW.P_CAN2_GW2_C10_0 <-> outer port HALP_CAN2_GW2_C10_0
    delegate SWC_CGW.P_CAN2_GW2_CE1000_0 <-> outer port HALP_CAN2_GW2_CE1000_0
    delegate SWC_CGW.P_CAN2_CGW_GW2_CE100_0 <-> outer port HALP_CAN2_CGW_GW2_CE100_0
    delegate SWC_CGW.P_CAN2_CGW_GW2_CE100_1 <-> outer port HALP_CAN2_CGW_GW2_CE100_1
    delegate SWC_CGW.P_CAN2_GW2_CE100_2 <-> outer port HALP_CAN2_GW2_CE100_2
    delegate SWC_CGW.P_CAN2_CGW_GW2_CE200_0 <-> outer port HALP_CAN2_CGW_GW2_CE200_0
    delegate SWC_CGW.P_CAN3_CGW_FD3_C100_0 <-> outer port HALP_CAN3_CGW_FD3_C100_0
    delegate SWC_CGW.P_CAN3_GW3_CE100_0 <-> outer port HALP_CAN3_GW3_CE100_0
    delegate SWC_CGW.P_CAN4_CGW_GW4_CE100_0 <-> outer port HALP_CAN4_CGW_GW4_CE100_0
    delegate SWC_CGW.P_CAN4_GW4_CE200_0 <-> outer port HALP_CAN4_GW4_CE200_0
    delegate SWC_CGW.P_CAN5_CGW_GW5_CE100_0 <-> outer port HALP_CAN5_CGW_GW5_CE100_0
    delegate SWC_CGW.P_CAN6_CGW_GW6_CE100_0 <-> outer port HALP_CAN6_CGW_GW6_CE100_0
    delegate SWC_CGW.P_CAN7_GW7_C100_0 <-> outer port HALP_CAN7_GW7_C100_0
    connect SWC_CDD.P_HALINCDD -> SWC_HALIN_CDD.R_HALINCDD
    connect SWC_UDS.P_UDSCDD -> SWC_HALIN_CDD.R_UDSCDD
    connect SWC_CDD.P_HALINCDD -> SWC_HALOUT.R_HALINCDD
    connect SWC_CDD.P_HALINCDD -> SWC_VES.R_HALINCDD
    connect SWC_CDD.P_HALOUTCDD -> SWC_HALOUT.R_HALOUTCDD
    connect SWC_DID.P_DIDReadCDD -> SWC_HALIN_CDD.R_DIDReadCDD
    connect SWC_DID.P_DIDWriteCDD -> SWC_HALOUT.R_DIDWriteCDD
    connect SWC_DKC.P_DKCCDD -> SWC_DKC.R_DKCCDD
    connect SWC_TPMS_APS.P_HALIN_TPMS_APS -> SWC_TPMS_APS.R_HALIN_TPMS_APS
    connect SWC_TPMS_APS.P_HALOUT_TPMS_APS -> SWC_TPMS_APS.R_HALOUT_TPMS_APS
    connect SWC_DKC.P_DKCData -> SWC_HALIN_CDD.R_DKCData
    connect SWC_DKC.P_UWBStatusData -> SWC_HALIN_CDD.R_UWBStatusData
    connect SWC_OUTP.P_BOUTP2_outputs -> SWC_TPMS_APS.R_BOUTP2_outputs
    connect SWC_TPMS_APS.P_BTPMS_APS_outputs -> SWC_HALIN_CDD.R_BTPMS_APS_outputs
    connect SWC_HALOUT.P_AppModeReq -> BswMTest.R_AppModeReq
    connect SWC_HALOUT.P_E2E_CAN3_VCU1 -> SWC_HALOUT.R_E2E_CAN3_VCU1
    connect SWC_HALOUT.P_E2E_CAN3_VCU1_toNIDEC -> SWC_HALOUT.R_E2E_CAN3_VCU1_toNIDEC
    connect SWC_HALOUT.P_E2E_CAN4_VCU1 -> SWC_HALOUT.R_E2E_CAN4_VCU1
    connect SWC_HALOUT.P_FDCCDD_Inner -> SWC_HALOUT.R_FDCCDD_Inner
    connect SWC_HALOUT.P_NVMWriteCDD_Inner -> SWC_HALOUT.R_NVMWriteCDD_Inner
    connect SWC_HALOUT.P_NVMWrite -> SWC_NVM.R_WriteNVData
    connect SWC_HALIN.P_WDGCDD -> SWC_HALIN.R_WDGCDD
    connect SWC_HALOUT.P_WDGCDD -> SWC_HALOUT.R_WDGCDD
    connect SWC_HALIN.P_BHAL_CAN2_outputs -> SWC_HALIN_CDD.R_BHAL_CAN2_outputs
    connect SWC_HALIN.P_BHAL_CAN4_outputs -> SWC_HALIN_CDD.R_BHAL_CAN4_outputs
    connect SWC_HALIN.P_BHAL_CAN{1..6}_outputs -> SWC_INP.R_BHAL_CAN{1..6}_outputs
    connect SWC_HALIN_CDD.P_BHAL_APM_outputs -> SWC_INP.R_BHAL_APM_outputs
    connect SWC_HALIN_CDD.P_BHAL_DDM_outputs -> SWC_INP.R_BHAL_DDM_outputs
    connect SWC_HALIN_CDD.P_BHAL_DKC_outputs -> SWC_INP.R_BHAL_DKC_outputs
    connect SWC_HALIN_CDD.P_BHAL_GPIO_outputs -> SWC_INP.R_BHAL_GPIO_outputs
    connect SWC_HALIN_CDD.P_BHAL_IMU_outputs -> SWC_INP.R_BHAL_IMU_outputs
    connect SWC_HALIN_CDD.P_BHAL_SYS_outputs -> SWC_INP.R_BHAL_SYS_outputs
    connect SWC_HALIN_CDD.P_BHAL_SYS_outputs -> SWC_HALOUT.R_BHAL_SYS_outputs
    connect SWC_HALIN_CDD.P_BHAL_TPMS_outputs -> SWC_INP.R_BHAL_TPMS_outputs
    connect SWC_IMU.P_HAINICDD_IMU -> SWC_HALIN_CDD.R_HALIN_IMU
    connect SWC_INP.P_BINP_CAN1_outputs -> SWC_FDC.R_BINP_CAN1_outputs
    connect SWC_INP.P_BINP_CAN1_outputs -> SWC_SCP.R_BINP_CAN1_outputs
    connect SWC_INP.P_BINP_CAN2_outputs -> SWC_FDC.R_BINP_CAN2_outputs
    connect SWC_INP.P_BINP_CAN2_outputs -> SWC_SCP.R_BINP_CAN2_outputs
    connect SWC_INP.P_BINP_CAN3_outputs -> SWC_FDC.R_BINP_CAN3_outputs
    connect SWC_INP.P_BINP_CAN3_outputs -> SWC_SCP.R_BINP_CAN3_outputs
    connect SWC_INP.P_BINP_CAN4_outputs -> SWC_FDC.R_BINP_CAN4_outputs
    connect SWC_INP.P_BINP_CAN4_outputs -> SWC_SCP.R_BINP_CAN4_outputs
    connect SWC_INP.P_BINP_CAN5_outputs -> SWC_FDC.R_BINP_CAN5_outputs
    connect SWC_INP.P_BINP_CAN5_outputs -> SWC_SCP.R_BINP_CAN5_outputs
    connect SWC_INP.P_BINP_CAN6_outputs -> SWC_FDC.R_BINP_CAN6_outputs
    connect SWC_INP.P_BINP_CAN6_outputs -> SWC_SCP.R_BINP_CAN6_outputs
    connect SWC_INP.P_BINP_APM_outputs -> SWC_FDC.R_BINP_APM_outputs
    connect SWC_INP.P_BINP_DDM_outputs -> SWC_FDC.R_BINP_DDM_outputs
    connect SWC_INP.P_BINP_DKC_outputs -> SWC_FDC.R_BINP_DKC_outputs
    connect SWC_INP.P_BINP_GPIO_outputs -> SWC_FDC.R_BINP_GPIO_outputs
    connect SWC_INP.P_BINP_IMU_outputs -> SWC_FDC.R_BINP_IMU_outputs
    connect SWC_INP.P_BINP_SYS_outputs -> SWC_FDC.R_BINP_SYS_outputs
    connect SWC_INP.P_BINP_TPMS_outputs -> SWC_FDC.R_BINP_TPMS_outputs
    connect SWC_FDC.P_BACC_outputs -> SWC_OUTP.R_BACC_outputs
    connect SWC_FDC.P_BAPM_outputs -> SWC_OUTP.R_BAPM_outputs
    connect SWC_FDC.P_BBCM_outputs -> SWC_OUTP.R_BBCM_outputs
    connect SWC_DDM.P_BDDM_outputs -> SWC_FDC.R_BDDM_outputs
    connect SWC_DDM.P_BDDM_outputs -> SWC_OUTP.R_BDDM_outputs
    connect SWC_FDC.P_BDHP_outputs -> SWC_OUTP.R_BDHP_outputs
    connect SWC_FDC.P_BDKC_outputs -> SWC_OUTP.R_BDKC_outputs
    connect SWC_FDC.P_BDSC_outputs -> SWC_OUTP.R_BDSC_outputs
    connect SWC_FDC.P_BNMM_outputs -> SWC_OUTP.R_BNMM_outputs
    connect SWC_FDC.P_BPMM_outputs -> SWC_OUTP.R_BPMM_outputs
    connect SWC_FDC.P_BSYS_outputs -> SWC_OUTP.R_BSYS_outputs
    connect SWC_FDC.P_BTHC_outputs -> SWC_OUTP.R_BTHC_outputs
    connect SWC_FDC.P_BTPM_outputs -> SWC_OUTP.R_BTPM_outputs
    connect SWC_FDC.P_BTQD_outputs -> SWC_OUTP.R_BTQD_outputs
    connect SWC_FDC.P_BTQR_outputs -> SWC_OUTP.R_BTQR_outputs
    connect SWC_V2L.P_BV2L_outputs -> SWC_OUTP.R_BV2L_outputs
    connect SWC_CARB.P_BDID_outputs -> SWC_OUTP.R_BDID_outputs
    connect SWC_FDC.P_BVMC_outputs -> SWC_OUTP.R_BVMC_outputs
    connect SWC_OUTP.P_BOUTP_outputs -> SWC_HALOUT.R_BOUTP_outputs
    connect SWC_HALIN_CDD.P_BHAL_DID_outputs -> SWC_HALOUT.R_BHAL_DID_outputs
    connect SWC_IOEXP.P_IOExpIN_CDD -> SWC_HALIN_CDD.R_IOExpIN_CDD
    connect SWC_IOEXP.P_IOExpOUT_CDD -> SWC_HALOUT.R_IOExpOUT_CDD
    connect SWC_NVM.P_ReadNVData -> SWC_HALIN.R_NVMRead
    connect SWC_HALIN.P_NVMReadCDD -> SWC_HALIN_CDD.R_NVMReadCDD
    connect SWC_HALIN.P_NVMReadCDD -> SWC_HALOUT.R_NVMReadCDD
    connect SWC_SCP.P_BSCP_outputs -> SWC_HALOUT.R_BSCP_outputs
    connect SWC_UART.P_UARTCDD -> SWC_UART.R_UARTCDD
    connect SWC_UDS.P_UDSCDD -> SWC_HALOUT.R_UDSCDD
    connect SWC_VES.P_CAN5_FD5_CONN1 -> SWC_HALIN_CDD.R_CAN5_FD5_CONN1
    connect SWC_VES.P_VESCDD -> SWC_VES.R_VESCDD
    connect SWC_INP.P_BINP_CAN{2..4}_outputs -> SWC_V2L.R_BINP_CAN{2..4}_outputs
    connect SWC_INP.P_BINP_SYS_outputs -> SWC_V2L.R_BINP_SYS_outputs
    connect SWC_FDC.P_BPMM_outputs -> SWC_V2L.R_BPMM_outputs
    connect SWC_FDC.P_BTQD_outputs -> SWC_V2L.R_BTQD_outputs
    connect SWC_INP.P_BINP_CAN{1..4}_outputs -> SWC_CARB.R_BINP_CAN{1..4}_outputs
    connect SWC_INP.P_BINP_DDM_outputs -> SWC_CARB.R_BINP_DDM_outputs
    connect SWC_INP.P_BINP_GPIO_outputs -> SWC_CARB.R_BINP_GPIO_outputs
    connect SWC_INP.P_BINP_SYS_outputs -> SWC_CARB.R_BINP_SYS_outputs
    connect SWC_DDM.P_BDDM_outputs -> SWC_CARB.R_BDDM_outputs
    connect SWC_FDC.P_BDHP_outputs -> SWC_CARB.R_BDHP_outputs
    connect SWC_FDC.P_BPMM_outputs -> SWC_CARB.R_BPMM_outputs
    connect SWC_FDC.P_BTQD_outputs -> SWC_CARB.R_BTQD_outputs
    connect SWC_INP.P_BINP_CAN{1..6}_outputs -> SWC_DDM.R_BINP_CAN{1..6}_outputs
    connect SWC_INP.P_BINP_DDM_outputs -> SWC_DDM.R_BINP_DDM_outputs
    connect SWC_INP.P_BINP_GPIO_outputs -> SWC_DDM.R_BINP_GPIO_outputs
    connect SWC_INP.P_BINP_SYS_outputs -> SWC_DDM.R_BINP_SYS_outputs
    connect SWC_FDC.P_BAPM_outputs -> SWC_DDM.R_BAPM_outputs
    connect SWC_FDC.P_BBCM_outputs -> SWC_DDM.R_BBCM_outputs
    connect SWC_FDC.P_BDHP_outputs -> SWC_DDM.R_BDHP_outputs
    connect SWC_FDC.P_BDKC_outputs -> SWC_DDM.R_BDKC_outputs
    connect SWC_FDC.P_BPMM_outputs -> SWC_DDM.R_BPMM_outputs
    connect SWC_FDC.P_BTPM_outputs -> SWC_DDM.R_BTPM_outputs
    connect SWC_FDC.P_BTQD_outputs -> SWC_DDM.R_BTQD_outputs
    connect SWC_FDC.P_BTQR_outputs -> SWC_DDM.R_BTQR_outputs
    connect SWC_FDC.P_BVMC_outputs -> SWC_DDM.R_BVMC_outputs
